# CPSW0_NUSS_MDIO register map
Vendor: Texas Instruments
Peripheral module from a debugger description file (folder J7VCL).
Registers are 32-bit, read-write, reset 0x0 unless marked. A register's access mark holds for its fields unless they carry their own. Offsets are as the file gives them; lines under a group give offsets from that group; [hi:lo] are bit positions; {n}, {i} and the like mark numbered series; 'fields as' and 'values as' point back to an identical list; <NAME> marks a mode.

## CPSW0_NUSS_MDIO
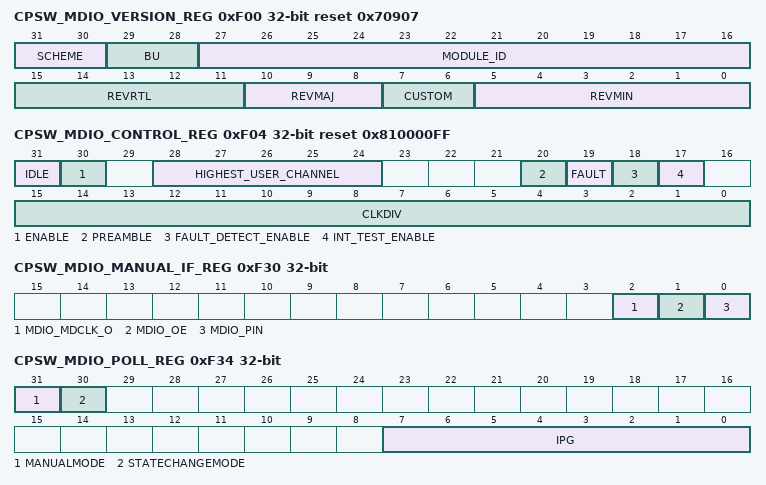
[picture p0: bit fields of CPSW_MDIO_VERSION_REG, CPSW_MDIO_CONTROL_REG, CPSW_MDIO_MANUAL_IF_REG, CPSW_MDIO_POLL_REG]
0xF00 CPSW_MDIO_VERSION_REG ro reset 0x70907 — MDIO Version Register.
  [31:30] SCHEME
  [29:28] BU
  [27:16] MODULE_ID
  [15:11] REVRTL — RTL version
  [10:8] REVMAJ — Major version
  [7:6] CUSTOM — Custom version
  [5:0] REVMIN — Minor version
0xF04 CPSW_MDIO_CONTROL_REG access per field reset 0x810000FF — MDIO Control Register
  [31] IDLE ro — MDIO state machine IDLE.
  [30] ENABLE rw — Enable control.
  [28:24] HIGHEST_USER_CHANNEL ro
  [20] PREAMBLE rw — Preamble disable.
  [19] FAULT rw — Fault indicator.
  [18] FAULT_DETECT_ENABLE rw
  [17] INT_TEST_ENABLE rw — Interrupt test enable.
  [15:0] CLKDIV rw — Clock Divider.
0xF08 CPSW_MDIO_ALIVE_REG — MDIO Alive Register.
  [31:0] ALIVE — MDIO Alive.
0xF0C CPSW_MDIO_LINK_REG ro — MDIO Link Register.
  [31:0] LINK — MDIO Link state.
0xF10 CPSW_MDIO_LINK_INT_RAW_REG — MDIO Link Interrupt Raw Register.
  [1:0] LINKINTRAW — MDIO link change event raw value.
0xF14 CPSW_MDIO_LINK_INT_MASKED_REG — MDIO Link Interrupt Masked Register.
  [1:0] LINKINTMASKED — MDIO link change interrupt masked value.
0xF18 CPSW_MDIO_LINK_INT_MASK_SET_REG — MDIO Link Interrupt Mask Set Register.
  [0] LINKINTMASKSET — MDIO link interrupt mask set.
0xF1C CPSW_MDIO_LINK_INT_MASK_CLEAR_REG — MDIO Link Interrupt Mask Clear Register.
  [0] LINKINTMASKCLR — MDIO link interrupt mask clear.
0xF20 CPSW_MDIO_USER_INT_RAW_REG — MDIO User Interrupt Raw Register.
  [1:0] USERINTRAW — Raw value of MDIO user command complete event for MDIOUserAccess1 through MDIOUserAccess0, respectively.
0xF24 CPSW_MDIO_USER_INT_MASKED_REG — MDIO User Interrupt Masked Register.
  [1:0] USERINTMASKED — Masked value of MDIO user command complete interrupt for MDIOUserAccess1 through MDIOUserAccess0, respectively.
0xF28 CPSW_MDIO_USER_INT_MASK_SET_REG — MDIO User Interrupt Mask Set Register.
  [1:0] USERINTMASKSET — MDIO user interrupt mask set for
0xF2C CPSW_MDIO_USER_INT_MASK_CLEAR_REG — MDIO User Interrupt Mask Clear Register
  [1:0] USERINTMASKCLR — MDIO user command complete interrupt mask clear for
0xF30 CPSW_MDIO_MANUAL_IF_REG — MDIO Manual Interface Register.
  [2] MDIO_MDCLK_O — MDIO Clock Output.
  [1] MDIO_OE — MDIO Output Enable.
  [0] MDIO_PIN — MDIO Pin Value.
0xF34 CPSW_MDIO_POLL_REG — MDIO Poll Register.
  [31] MANUALMODE — MDIO Manual Mode.
  [30] STATECHANGEMODE — MDIO State Change Mode.
  [7:0] IPG — Polling Inter Packet Gap Value.
0xF38 CPSW_MDIO_POLL_EN_REG reset 0xFFFFFFFF — MDIO Poll Enable Register.
  [31:0] POLL_EN — MDIO Poll Enable.
0xF3C CPSW_MDIO_CLAUS45_REG — MDIO Clause45 Enable Register.
  [31:0] CLAUSE45 — MDIO clause 45 mode.
0xF40 CPSW_MDIO_USER_ADDR0_REG — MDIO Address 0 Register.
  [15:0] USER_ADDR0 — MDIO User Address 0.
0xF44 CPSW_MDIO_USER_ADDR1_REG — MDIO Address 1 Register.
  [15:0] USER_ADDR1 — MDIO User Address 1.
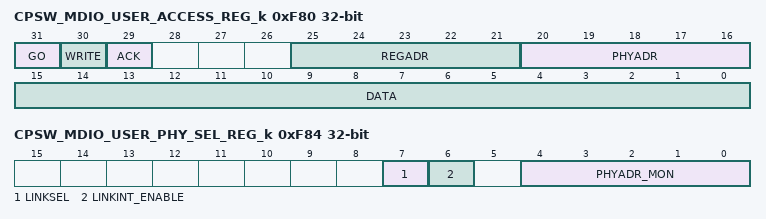
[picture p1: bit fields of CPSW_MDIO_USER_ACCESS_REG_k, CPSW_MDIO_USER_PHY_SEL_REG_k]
0xF80 CPSW_MDIO_USER_ACCESS_REG_k — MDIO User Access Register. Offset = F80h + (k * 8h); where k = 0h to 1h
  [31] GO
  [30] WRITE — Write enable.
  [29] ACK — Acknowledge.
  [25:21] REGADR — Register address.
  [20:16] PHYADR — PHY address.
  [15:0] DATA — User data.
0xF84 CPSW_MDIO_USER_PHY_SEL_REG_k — MDIO User PHY Select Register Offset = F84h + (k * 8h); where k = 0h to 1h
  [7] LINKSEL — Link status determination select.
  [6] LINKINT_ENABLE — Link change interrupt enable.
  [4:0] PHYADR_MON — PHY address whose link status is monitored.
